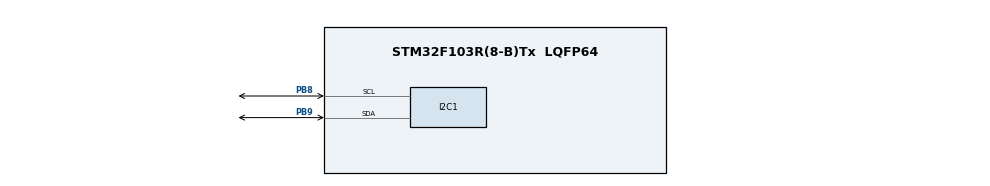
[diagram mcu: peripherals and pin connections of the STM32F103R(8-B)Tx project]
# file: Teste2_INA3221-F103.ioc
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Mcu.Family=STM32F1
Mcu.Name=STM32F103R(8-B)Tx
Mcu.Package=LQFP64
NVIC.PriorityGroup=NVIC_PRIORITYGROUP_4
PB8.Mode=I2C
PB8.Signal=I2C1_SCL
PB9.Mode=I2C
PB9.Signal=I2C1_SDA
ProjectManager.HeapSize=0x200
ProjectManager.StackSize=0x400
ProjectManager.TargetToolchain=STM32CubeIDE
RCC.APB1Freq_Value=8000000
RCC.APB2Freq_Value=8000000
board=custom

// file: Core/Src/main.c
/* USER CODE BEGIN Header */
/**
  ******************************************************************************
  * @file           : main.c
  * @brief          : Main program body
  ******************************************************************************
  * @attention
  *
  * Copyright (c) 2024 STMicroelectronics.
  * All rights reserved.
  *
  * This software is licensed under terms that can be found in the LICENSE file
  * in the root directory of this software component.
  * If no LICENSE file comes with this software, it is provided AS-IS.
  *
  ******************************************************************************
  */
/* USER CODE END Header */
#include "main.h"

/* USER CODE BEGIN Includes */
#include "stdbool.h"
#include "stdlib.h"
#include "stdio.h"
#include "inttypes.h"
#include "string.h"
#include "math.h"
#include "INA3221.h"
/* USER CODE END Includes */

/* USER CODE BEGIN PTD */

INA3221 ina;
/* USER CODE END PTD */

I2C_HandleTypeDef hi2c1;

void SystemClock_Config(void);
static void MX_GPIO_Init(void);
static void MX_I2C1_Init(void);

int main(void)
{

  /* MCU Configuration--------------------------------------------------------*/

  /* Reset of all peripherals, Initializes the Flash interface and the Systick. */
  HAL_Init();

  /* Configure the system clock */
  SystemClock_Config();

  /* Initialize all configured peripherals */
  MX_GPIO_Init();
  MX_I2C1_Init();
  /* USER CODE BEGIN 2 */
  ina.ADDR = INA3221_ADDRESS0;
  ina.CHANNEL1_ENABLE = INA3221_CONFIG_ENABLE_CHAN1;
  ina.CHANNEL2_ENABLE = INA3221_CONFIG_ENABLE_CHAN2;
  ina.CHANNEL3_ENABLE = INA3221_CONFIG_ENABLE_CHAN3;
  ina.AVG = INA3221_CONFIG_AVG_64;
  ina.VBUS_CT = INA3221_CONFIG_VBUS_CT1;
  ina.VSH_CT = INA3221_CONFIG_VSH_CT1;
  for(uint8_t i = 0; i<3; i++){
	  ina.SHUNTR[i] = SHUNT_100m;
	  ina.CRIT_CURR[i] = 15;
	  ina.WARN_CURR[i] = 15;

	  ina.CRIT_FLAG[i] = 0;
	  ina.WARN_FLAG[i] = 0;
  }
  INA3221_Begin(&hi2c1, &ina, 0);

  /* USER CODE END 2 */

  /* Infinite loop */
  /* USER CODE BEGIN WHILE */
  while (1)
  {
	  INA3221_read(&ina);

    /* USER CODE END WHILE */

  }
}

void SystemClock_Config(void)
{
  RCC_OscInitTypeDef RCC_OscInitStruct = {0};
  RCC_ClkInitTypeDef RCC_ClkInitStruct = {0};

  /** Initializes the RCC Oscillators according to the specified parameters
  * in the RCC_OscInitTypeDef structure.
  */
  RCC_OscInitStruct.OscillatorType = RCC_OSCILLATORTYPE_HSI;
  RCC_OscInitStruct.HSIState = RCC_HSI_ON;
  RCC_OscInitStruct.HSICalibrationValue = RCC_HSICALIBRATION_DEFAULT;
  RCC_OscInitStruct.PLL.PLLState = RCC_PLL_NONE;
  if (HAL_RCC_OscConfig(&RCC_OscInitStruct) != HAL_OK)
  {
    Error_Handler();
  }

  /** Initializes the CPU, AHB and APB buses clocks
  */
  RCC_ClkInitStruct.ClockType = RCC_CLOCKTYPE_HCLK|RCC_CLOCKTYPE_SYSCLK
                              |RCC_CLOCKTYPE_PCLK1|RCC_CLOCKTYPE_PCLK2;
  RCC_ClkInitStruct.SYSCLKSource = RCC_SYSCLKSOURCE_HSI;
  RCC_ClkInitStruct.AHBCLKDivider = RCC_SYSCLK_DIV1;
  RCC_ClkInitStruct.APB1CLKDivider = RCC_HCLK_DIV1;
  RCC_ClkInitStruct.APB2CLKDivider = RCC_HCLK_DIV1;

  if (HAL_RCC_ClockConfig(&RCC_ClkInitStruct, FLASH_LATENCY_0) != HAL_OK)
  {
    Error_Handler();
  }
}

static void MX_I2C1_Init(void)
{

  hi2c1.Instance = I2C1;
  hi2c1.Init.ClockSpeed = 100000;
  hi2c1.Init.DutyCycle = I2C_DUTYCYCLE_2;
  hi2c1.Init.OwnAddress1 = 0;
  hi2c1.Init.AddressingMode = I2C_ADDRESSINGMODE_7BIT;
  hi2c1.Init.DualAddressMode = I2C_DUALADDRESS_DISABLE;
  hi2c1.Init.OwnAddress2 = 0;
  hi2c1.Init.GeneralCallMode = I2C_GENERALCALL_DISABLE;
  hi2c1.Init.NoStretchMode = I2C_NOSTRETCH_DISABLE;
  if (HAL_I2C_Init(&hi2c1) != HAL_OK)
  {
    Error_Handler();
  }

}

static void MX_GPIO_Init(void)
{

  /* GPIO Ports Clock Enable */
  __HAL_RCC_GPIOB_CLK_ENABLE();

}

void Error_Handler(void)
{
  __disable_irq();
  while (1)
  {
  }
}
